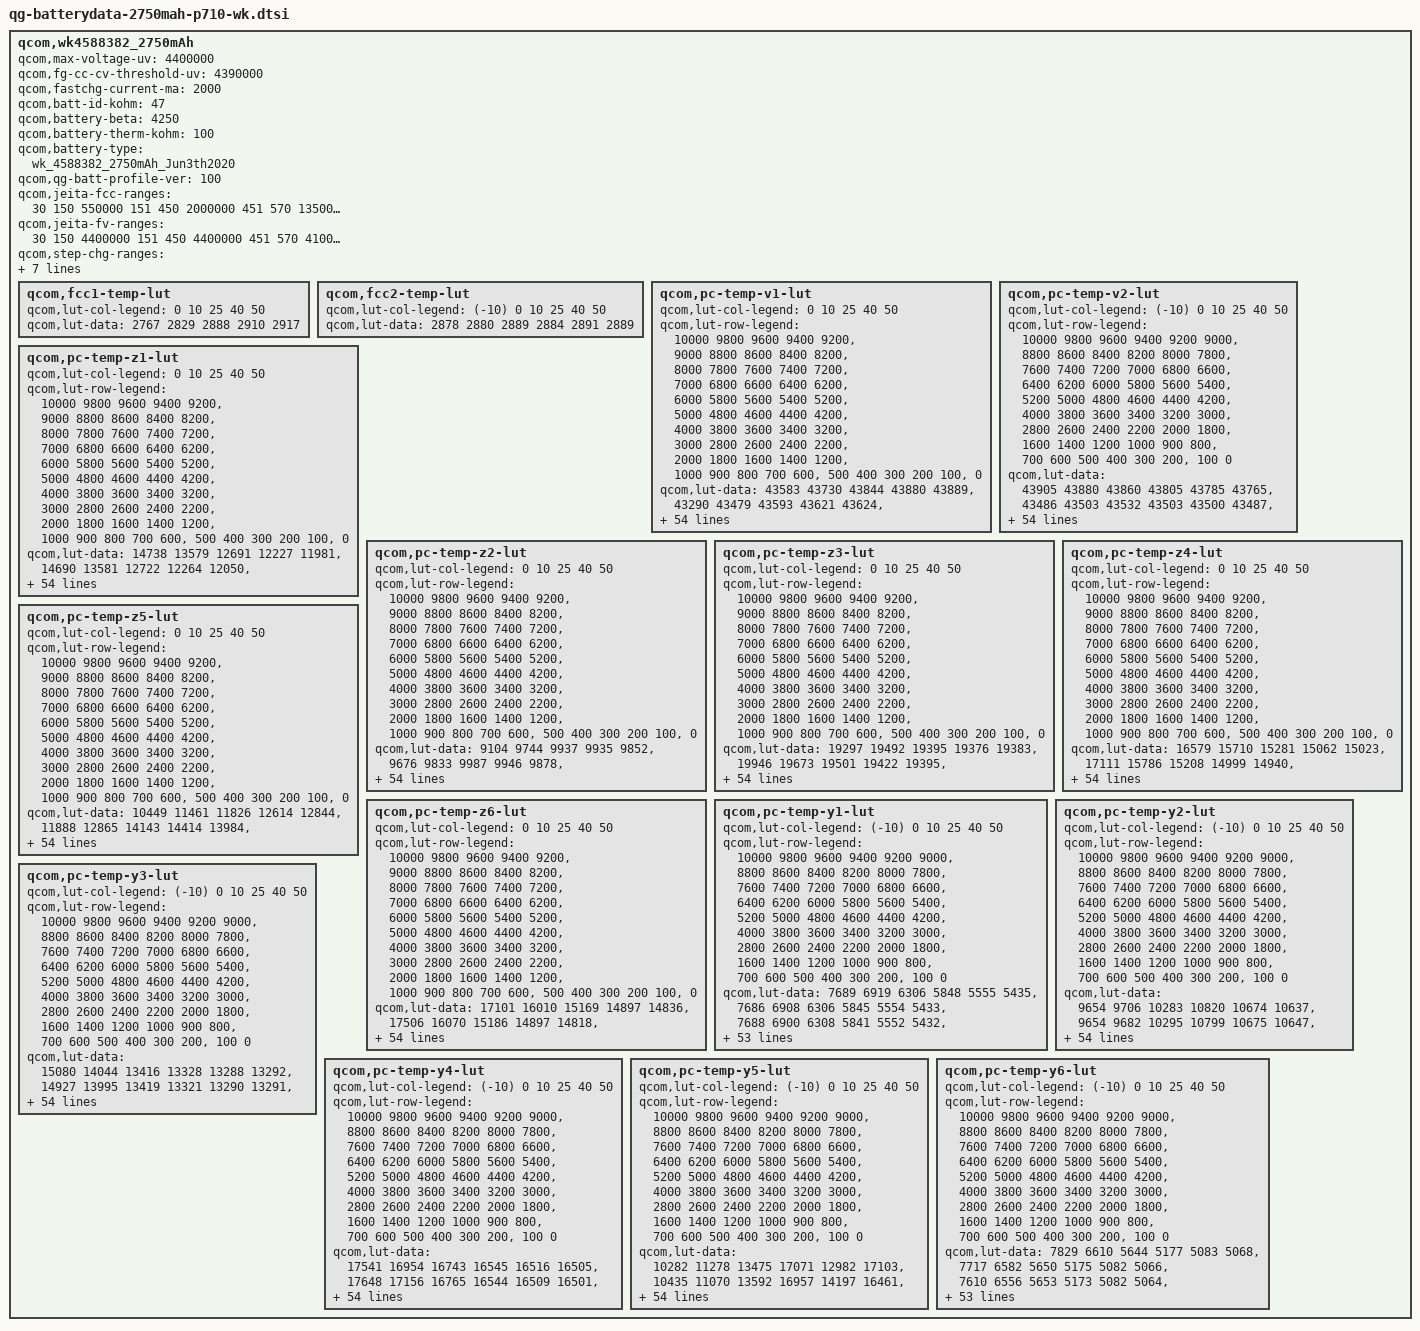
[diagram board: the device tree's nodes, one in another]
/*
 * Copyright (c) 2018-2019, The Linux Foundation. All rights reserved.
 *
 * This program is free software; you can redistribute it and/or modify
 * it under the terms of the GNU General Public License version 2 and
 * only version 2 as published by the Free Software Foundation.
 *
 * This program is distributed in the hope that it will be useful,
 * but WITHOUT ANY WARRANTY; without even the implied warranty of
 * MERCHANTABILITY or FITNESS FOR A PARTICULAR PURPOSE.  See the
 * GNU General Public License for more details.
 */

qcom,wk4588382_2750mAh {
	/* wk4588382_2750mAh_averaged_MasterSlave_Jun3th2020 */
	qcom,max-voltage-uv = <4400000>;
	qcom,fg-cc-cv-threshold-uv = <4390000>;
	qcom,fastchg-current-ma = <2000>;
	qcom,batt-id-kohm = <47>;
	qcom,battery-beta = <4250>;
	qcom,battery-therm-kohm = <100>;
	qcom,battery-type = "wk_4588382_2750mAh_Jun3th2020";
	qcom,qg-batt-profile-ver = <100>;

	qcom,jeita-fcc-ranges = <30  150   550000
				151  450  2000000
				451  570  1350000>;
	qcom,jeita-fv-ranges = <30   150   4400000
				151  450  4400000
				451  570  4100000>;
	qcom,step-chg-ranges = <3600000  3800000  5400000
				3800001  4300000  3600000
				4300001  4350000  2500000>;
	qcom,ocv-based-step-chg;

	/* COOL = 15 DegC, WARM = 45 DegC */
	qcom,jeita-soft-thresholds = <0x45E7 0x20C1>;
	
	/* COLD = 3 DegC, HOT = 57 DegC */
	qcom,jeita-hard-thresholds = <0x54E5 0x1694>;
	
	/* COOL hys = 17 DegC, WARM hys = 42 DegC */
	qcom,jeita-soft-hys-thresholds = <0x4341 0x23D3>;
	
	qcom,jeita-soft-fcc-ua = <550000 1350000>;
	qcom,jeita-soft-fv-uv = <4400000 4100000>;

	qcom,fcc1-temp-lut {
		qcom,lut-col-legend = <0 10 25 40 50>;
		qcom,lut-data = <2767 2829 2888 2910 2917>;
	};

	qcom,fcc2-temp-lut {
		qcom,lut-col-legend = <(-10) 0 10 25 40 50>;
		qcom,lut-data = <2878 2880 2889 2884 2891 2889>;
	};

	qcom,pc-temp-v1-lut {
		qcom,lut-col-legend = <0 10 25 40 50>;
		qcom,lut-row-legend = <10000 9800 9600 9400 9200>,
			<9000 8800 8600 8400 8200>,
			<8000 7800 7600 7400 7200>,
			<7000 6800 6600 6400 6200>,
			<6000 5800 5600 5400 5200>,
			<5000 4800 4600 4400 4200>,
			<4000 3800 3600 3400 3200>,
			<3000 2800 2600 2400 2200>,
			<2000 1800 1600 1400 1200>,
			<1000 900 800 700 600>,
			<500 400 300 200 100>,
			<0>;
		qcom,lut-data = <43583 43730 43844 43880 43889>,
			<43290 43479 43593 43621 43624>,
			<43034 43220 43347 43384 43385>,
			<42791 42977 43105 43149 43154>,
			<42556 42738 42863 42910 42921>,
			<42330 42500 42624 42670 42689>,
			<42113 42269 42385 42435 42455>,
			<41904 42047 42150 42203 42219>,
			<41698 41833 41921 41971 41986>,
			<41493 41622 41697 41738 41754>,
			<41293 41411 41475 41511 41526>,
			<41111 41210 41254 41289 41305>,
			<40939 41034 41048 41072 41089>,
			<40728 40865 40872 40865 40877>,
			<40425 40642 40696 40663 40670>,
			<40132 40327 40464 40464 40470>,
			<39949 40065 40191 40264 40277>,
			<39811 39919 39994 40078 40095>,
			<39681 39804 39869 39913 39925>,
			<39560 39683 39747 39756 39761>,
			<39442 39563 39596 39595 39597>,
			<39324 39421 39425 39432 39434>,
			<39205 39222 39208 39242 39249>,
			<39088 39007 38929 38993 39010>,
			<38973 38820 38740 38784 38798>,
			<38857 38650 38645 38663 38667>,
			<38735 38539 38570 38569 38564>,
			<38613 38474 38491 38473 38465>,
			<38514 38421 38416 38380 38371>,
			<38431 38373 38344 38296 38287>,
			<38366 38330 38274 38221 38212>,
			<38317 38290 38212 38155 38143>,
			<38279 38253 38160 38100 38081>,
			<38245 38218 38113 38050 38023>,
			<38216 38185 38074 38001 37968>,
			<38187 38151 38041 37952 37914>,
			<38163 38116 38002 37903 37858>,
			<38138 38079 37961 37857 37800>,
			<38099 38030 37908 37803 37734>,
			<38027 37946 37830 37725 37652>,
			<37935 37838 37724 37622 37552>,
			<37818 37720 37609 37507 37438>,
			<37679 37582 37476 37372 37303>,
			<37520 37420 37320 37220 37151>,
			<37367 37273 37168 37073 37006>,
			<37253 37190 37073 36983 36925>,
			<37215 37159 37049 36958 36900>,
			<37187 37131 37032 36941 36882>,
			<37164 37108 37014 36923 36865>,
			<37127 37073 36976 36878 36813>,
			<36954 36887 36774 36652 36566>,
			<36534 36469 36350 36218 36123>,
			<35968 35898 35779 35645 35550>,
			<35199 35119 34998 34863 34765>,
			<33992 33914 33795 33656 33553>,
			<30000 30000 30000 30000 30000>;
	};

	qcom,pc-temp-v2-lut {
		qcom,lut-col-legend = <(-10) 0 10 25 40 50>;
		qcom,lut-row-legend = <10000 9800 9600 9400 9200 9000>,
			<8800 8600 8400 8200 8000 7800>,
			<7600 7400 7200 7000 6800 6600>,
			<6400 6200 6000 5800 5600 5400>,
			<5200 5000 4800 4600 4400 4200>,
			<4000 3800 3600 3400 3200 3000>,
			<2800 2600 2400 2200 2000 1800>,
			<1600 1400 1200 1000 900 800>,
			<700 600 500 400 300 200>,
			<100 0>;
		qcom,lut-data = <43905 43880 43860 43805 43785 43765>,
			<43486 43503 43532 43503 43500 43487>,
			<43110 43157 43228 43220 43231 43222>,
			<42782 42845 42950 42958 42977 42970>,
			<42493 42561 42696 42715 42739 42731>,
			<42226 42302 42448 42476 42503 42494>,
			<41976 42072 42201 42240 42267 42259>,
			<41744 41847 41962 42008 42033 42026>,
			<41515 41590 41731 41781 41802 41796>,
			<41304 41332 41507 41556 41575 41568>,
			<41174 41157 41293 41332 41350 41344>,
			<41105 41051 41090 41109 41130 41127>,
			<41000 40912 40893 40901 40915 40913>,
			<40566 40634 40712 40727 40710 40705>,
			<40003 40291 40521 40553 40509 40502>,
			<39715 40006 40266 40322 40311 40306>,
			<39527 39743 39961 40047 40115 40117>,
			<39348 39517 39746 39847 39935 39937>,
			<39172 39329 39613 39723 39772 39769>,
			<39002 39152 39472 39594 39606 39600>,
			<38833 38974 39258 39406 39430 39429>,
			<38673 38801 39016 39187 39245 39251>,
			<38544 38633 38824 38977 39038 39047>,
			<38438 38466 38659 38769 38808 38813>,
			<38346 38337 38517 38600 38627 38630>,
			<38267 38250 38395 38476 38501 38503>,
			<38197 38180 38286 38371 38394 38395>,
			<38134 38118 38181 38272 38294 38294>,
			<38076 38064 38085 38183 38204 38203>,
			<38020 38016 38013 38103 38121 38118>,
			<37965 37972 37959 38031 38045 38041>,
			<37912 37931 37912 37963 37975 37970>,
			<37862 37892 37871 37901 37916 37911>,
			<37812 37853 37833 37842 37858 37852>,
			<37761 37812 37797 37790 37792 37779>,
			<37709 37769 37760 37742 37719 37694>,
			<37653 37722 37717 37689 37639 37602>,
			<37595 37673 37666 37626 37550 37499>,
			<37531 37616 37606 37557 37463 37400>,
			<37458 37544 37533 37482 37385 37319>,
			<37378 37459 37446 37399 37307 37241>,
			<37298 37359 37342 37304 37214 37150>,
			<37219 37239 37216 37188 37098 37035>,
			<37134 37105 37082 37049 36965 36903>,
			<37048 36974 36948 36912 36838 36781>,
			<36959 36894 36871 36871 36812 36756>,
			<36915 36863 36840 36858 36800 36746>,
			<36865 36832 36809 36838 36784 36731>,
			<36798 36787 36760 36810 36758 36703>,
			<36673 36701 36664 36733 36660 36590>,
			<36428 36480 36435 36456 36328 36239>,
			<36001 36041 35959 35961 35817 35726>,
			<35376 35408 35310 35322 35155 35058>,
			<34467 34497 34391 34466 34262 34161>,
			<32983 33139 33114 33148 32998 32889>,
			<28849 28709 27892 28006 28079 28058>;
	};

	qcom,pc-temp-z1-lut {
		qcom,lut-col-legend = <0 10 25 40 50>;
		qcom,lut-row-legend = <10000 9800 9600 9400 9200>,
			<9000 8800 8600 8400 8200>,
			<8000 7800 7600 7400 7200>,
			<7000 6800 6600 6400 6200>,
			<6000 5800 5600 5400 5200>,
			<5000 4800 4600 4400 4200>,
			<4000 3800 3600 3400 3200>,
			<3000 2800 2600 2400 2200>,
			<2000 1800 1600 1400 1200>,
			<1000 900 800 700 600>,
			<500 400 300 200 100>,
			<0>;
		qcom,lut-data = <14738 13579 12691 12227 11981>,
			<14690 13581 12722 12264 12050>,
			<14733 13571 12731 12247 12046>,
			<14751 13561 12729 12235 12037>,
			<14702 13551 12720 12222 12028>,
			<14639 13539 12708 12209 12022>,
			<14623 13530 12687 12199 12018>,
			<14616 13529 12666 12191 12016>,
			<14608 13531 12658 12187 12013>,
			<14590 13525 12651 12183 12009>,
			<14562 13514 12652 12181 12006>,
			<14525 13500 12658 12180 12004>,
			<14475 13474 12661 12178 12003>,
			<14449 13437 12651 12176 12001>,
			<14442 13412 12636 12172 11999>,
			<14435 13389 12626 12170 11998>,
			<14417 13379 12619 12168 12000>,
			<14391 13382 12618 12168 12001>,
			<14386 13390 12624 12169 12001>,
			<14403 13405 12628 12170 12001>,
			<14419 13432 12632 12169 12000>,
			<14414 13445 12639 12168 11999>,
			<14396 13443 12640 12167 11999>,
			<14392 13441 12637 12169 12001>,
			<14421 13446 12637 12172 12003>,
			<14455 13459 12642 12175 12006>,
			<14474 13464 12649 12180 12010>,
			<14487 13466 12654 12183 12014>,
			<14489 13471 12659 12187 12017>,
			<14465 13482 12665 12191 12021>,
			<14444 13496 12676 12196 12025>,
			<14459 13498 12684 12202 12028>,
			<14488 13489 12687 12207 12032>,
			<14496 13483 12690 12212 12035>,
			<14491 13489 12690 12217 12039>,
			<14493 13503 12690 12222 12044>,
			<14513 13521 12694 12227 12049>,
			<14547 13547 12704 12231 12053>,
			<14580 13562 12715 12236 12056>,
			<14621 13565 12721 12242 12061>,
			<14643 13567 12726 12247 12066>,
			<14624 13580 12734 12254 12070>,
			<14603 13603 12744 12261 12073>,
			<14641 13622 12751 12265 12076>,
			<14665 13627 12757 12268 12078>,
			<14653 13621 12751 12270 12079>,
			<14680 13620 12745 12269 12080>,
			<14639 13618 12752 12273 12082>,
			<14759 13629 12759 12278 12085>,
			<14655 13636 12758 12283 12094>,
			<14676 13662 12782 12293 12102>,
			<14718 13664 12779 12306 12113>,
			<14746 13706 12828 12319 12126>,
			<14813 13781 12830 12341 12146>,
			<14813 13781 12830 12341 12146>,
			<14813 13781 12830 12341 12146>;
	};

	qcom,pc-temp-z2-lut {
		qcom,lut-col-legend = <0 10 25 40 50>;
		qcom,lut-row-legend = <10000 9800 9600 9400 9200>,
			<9000 8800 8600 8400 8200>,
			<8000 7800 7600 7400 7200>,
			<7000 6800 6600 6400 6200>,
			<6000 5800 5600 5400 5200>,
			<5000 4800 4600 4400 4200>,
			<4000 3800 3600 3400 3200>,
			<3000 2800 2600 2400 2200>,
			<2000 1800 1600 1400 1200>,
			<1000 900 800 700 600>,
			<500 400 300 200 100>,
			<0>;
		qcom,lut-data = <9104 9744 9937 9935 9852>,
			<9676 9833 9987 9946 9878>,
			<9710 9839 9998 9979 9871>,
			<9722 9820 9990 10025 10016>,
			<9729 9798 9959 10005 9987>,
			<9733 9777 9929 9977 9947>,
			<9741 9759 9898 9957 9935>,
			<9752 9745 9879 9940 9932>,
			<9755 9734 9884 9938 9934>,
			<9750 9728 9900 9942 9943>,
			<9742 9724 9908 9943 9947>,
			<9737 9722 9911 9939 9903>,
			<9731 9740 9915 9934 9844>,
			<9719 9776 9930 9919 9841>,
			<9672 9785 9946 9893 9849>,
			<9631 9782 9945 9890 9854>,
			<9633 9780 9940 9922 9860>,
			<9646 9794 9939 9941 9865>,
			<9659 9821 9948 9924 9874>,
			<9673 9843 9960 9904 9888>,
			<9683 9866 9973 9904 9904>,
			<9685 9875 9984 9910 9925>,
			<9686 9873 9984 9918 9941>,
			<9687 9868 9977 9941 9952>,
			<9688 9852 9971 9958 9966>,
			<9690 9817 9966 9950 10037>,
			<9696 9807 9964 9937 10138>,
			<9706 9830 9973 9951 10129>,
			<9716 9855 9994 9986 10010>,
			<9726 9862 9997 9998 9907>,
			<9735 9867 9979 9974 9833>,
			<9743 9872 9967 9943 9789>,
			<9750 9878 9969 9919 9794>,
			<9761 9885 9974 9900 9812>,
			<9782 9893 9980 9908 9833>,
			<9795 9901 9993 9965 9861>,
			<9722 9909 10006 10005 9893>,
			<9589 9917 10020 10020 9931>,
			<9564 9927 10036 10028 9964>,
			<9620 9942 10056 10036 9982>,
			<9702 9955 10075 10055 9994>,
			<9869 9957 10085 10073 9999>,
			<10039 9958 10090 10099 9999>,
			<9973 9969 10094 10099 9997>,
			<9918 9993 10106 10082 9988>,
			<9913 12962 10144 10046 9973>,
			<9777 13619 10131 10041 9983>,
			<9969 10888 10120 10045 9998>,
			<9985 16588 10135 10053 10030>,
			<9920 12525 10180 10122 10092>,
			<9695 14166 10223 10077 9975>,
			<9622 13638 10223 9990 9860>,
			<9549 10993 10191 9962 9824>,
			<9425 9996 10134 9918 9797>,
			<9425 9996 10134 9918 9797>,
			<9425 9996 10134 9918 9797>;
	};

	qcom,pc-temp-z3-lut {
		qcom,lut-col-legend = <0 10 25 40 50>;
		qcom,lut-row-legend = <10000 9800 9600 9400 9200>,
			<9000 8800 8600 8400 8200>,
			<8000 7800 7600 7400 7200>,
			<7000 6800 6600 6400 6200>,
			<6000 5800 5600 5400 5200>,
			<5000 4800 4600 4400 4200>,
			<4000 3800 3600 3400 3200>,
			<3000 2800 2600 2400 2200>,
			<2000 1800 1600 1400 1200>,
			<1000 900 800 700 600>,
			<500 400 300 200 100>,
			<0>;
		qcom,lut-data = <19297 19492 19395 19376 19383>,
			<19946 19673 19501 19422 19395>,
			<20080 19782 19535 19431 19411>,
			<20109 19817 19588 19487 19464>,
			<20104 19832 19596 19503 19471>,
			<20095 19836 19599 19509 19473>,
			<20072 19835 19599 19502 19471>,
			<20030 19826 19599 19487 19466>,
			<20007 19809 19590 19480 19462>,
			<19997 19798 19569 19476 19459>,
			<19988 19792 19560 19471 19455>,
			<19959 19785 19558 19461 19443>,
			<19909 19753 19554 19450 19430>,
			<19898 19700 19534 19443 19424>,
			<20008 19690 19513 19436 19421>,
			<20117 19722 19515 19435 19417>,
			<20095 19744 19526 19435 19414>,
			<20014 19720 19527 19435 19409>,
			<19951 19678 19507 19425 19401>,
			<19905 19653 19490 19413 19392>,
			<19876 19635 19495 19412 19390>,
			<19871 19629 19504 19413 19390>,
			<19868 19670 19510 19414 19390>,
			<19870 19717 19515 19413 19388>,
			<19888 19722 19516 19412 19387>,
			<19912 19723 19504 19410 19406>,
			<19936 19722 19491 19407 19440>,
			<19959 19717 19496 19420 19452>,
			<19964 19709 19511 19464 19459>,
			<19955 19702 19525 19481 19461>,
			<19942 19695 19540 19478 19451>,
			<19926 19687 19548 19471 19437>,
			<19904 19678 19543 19461 19429>,
			<19879 19671 19535 19448 19421>,
			<19849 19667 19525 19439 19412>,
			<19804 19663 19514 19432 19400>,
			<19616 19659 19507 19426 19394>,
			<19338 19652 19503 19421 19395>,
			<19269 19647 19499 19417 19395>,
			<19267 19645 19494 19413 19394>,
			<19266 19642 19488 19409 19391>,
			<19264 19639 19482 19408 19391>,
			<19262 19632 19475 19411 19395>,
			<19262 19626 19474 19412 19399>,
			<19262 19567 19471 19410 19401>,
			<19262 19298 19448 19392 19381>,
			<19263 19261 19434 19385 19372>,
			<19261 19261 19417 19379 19366>,
			<19261 19257 19408 19377 19353>,
			<19262 19260 19399 19368 19343>,
			<19264 19257 19391 19385 19383>,
			<19265 19258 19385 19398 19395>,
			<19267 19259 19382 19403 19398>,
			<19270 19263 19397 19405 19403>,
			<19270 19263 19397 19405 19403>,
			<19270 19263 19397 19405 19403>;
	};

	qcom,pc-temp-z4-lut {
		qcom,lut-col-legend = <0 10 25 40 50>;
		qcom,lut-row-legend = <10000 9800 9600 9400 9200>,
			<9000 8800 8600 8400 8200>,
			<8000 7800 7600 7400 7200>,
			<7000 6800 6600 6400 6200>,
			<6000 5800 5600 5400 5200>,
			<5000 4800 4600 4400 4200>,
			<4000 3800 3600 3400 3200>,
			<3000 2800 2600 2400 2200>,
			<2000 1800 1600 1400 1200>,
			<1000 900 800 700 600>,
			<500 400 300 200 100>,
			<0>;
		qcom,lut-data = <16579 15710 15281 15062 15023>,
			<17111 15786 15208 14999 14940>,
			<16830 15977 15100 14908 14869>,
			<16535 15690 15257 15046 14978>,
			<16266 15432 15132 14993 14946>,
			<16022 15283 15024 14925 14894>,
			<15851 15169 14955 14885 14861>,
			<15714 15085 14902 14854 14834>,
			<15599 15021 14866 14834 14816>,
			<15495 14968 14840 14820 14804>,
			<15411 14921 14823 14810 14796>,
			<15354 14886 14813 14801 14792>,
			<15312 14868 14802 14793 14788>,
			<15250 14856 14782 14782 14781>,
			<15122 14852 14766 14770 14769>,
			<15016 14851 14769 14758 14758>,
			<14999 14850 14781 14747 14749>,
			<14992 14834 14782 14739 14741>,
			<14989 14811 14751 14731 14733>,
			<14988 14802 14726 14726 14727>,
			<14986 14797 14728 14728 14728>,
			<14976 14796 14734 14737 14738>,
			<14955 14817 14779 14763 14760>,
			<14932 14857 14933 14885 14868>,
			<14899 14910 15004 14970 14954>,
			<14873 14979 14990 14961 14925>,
			<14867 14999 14963 14937 14862>,
			<14864 14971 14928 14896 14822>,
			<14864 14932 14879 14824 14790>,
			<14869 14903 14839 14782 14769>,
			<14873 14875 14802 14766 14759>,
			<14868 14851 14779 14755 14752>,
			<14858 14829 14769 14746 14742>,
			<14856 14809 14762 14740 14734>,
			<14863 14792 14756 14739 14733>,
			<14876 14777 14750 14742 14736>,
			<15043 14767 14748 14743 14740>,
			<15333 14759 14746 14743 14743>,
			<15401 14756 14745 14743 14746>,
			<15384 14760 14751 14749 14751>,
			<15368 14765 14761 14759 14757>,
			<15361 14763 14760 14759 14757>,
			<15355 14758 14750 14746 14746>,
			<15336 14756 14748 14746 14746>,
			<15247 14788 14745 14749 14750>,
			<15170 14994 14708 14715 14714>,
			<15163 15026 14707 14708 14708>,
			<15156 15015 14704 14686 14686>,
			<15147 15008 14699 14661 14666>,
			<15133 14997 14702 14664 14667>,
			<15135 15009 14737 14689 14680>,
			<15164 15029 14757 14697 14692>,
			<15183 15038 14767 14697 14695>,
			<15210 15046 14757 14701 14693>,
			<15210 15046 14757 14701 14693>,
			<15210 15046 14757 14701 14693>;
	};

	qcom,pc-temp-z5-lut {
		qcom,lut-col-legend = <0 10 25 40 50>;
		qcom,lut-row-legend = <10000 9800 9600 9400 9200>,
			<9000 8800 8600 8400 8200>,
			<8000 7800 7600 7400 7200>,
			<7000 6800 6600 6400 6200>,
			<6000 5800 5600 5400 5200>,
			<5000 4800 4600 4400 4200>,
			<4000 3800 3600 3400 3200>,
			<3000 2800 2600 2400 2200>,
			<2000 1800 1600 1400 1200>,
			<1000 900 800 700 600>,
			<500 400 300 200 100>,
			<0>;
		qcom,lut-data = <10449 11461 11826 12614 12844>,
			<11888 12865 14143 14414 13984>,
			<12337 13125 15584 15732 15728>,
			<12574 13631 14605 15094 15762>,
			<12745 14173 15077 15717 15956>,
			<12846 14643 15646 16367 16209>,
			<12883 15028 16348 16491 16562>,
			<12897 15250 16986 16555 17035>,
			<12928 15413 17300 16742 17457>,
			<13073 15702 17521 17160 17896>,
			<13198 16483 17924 17339 18090>,
			<13065 17111 18684 17185 17608>,
			<12687 16685 19071 17036 16985>,
			<12711 15712 18591 17115 17064>,
			<15464 15927 17990 17382 17565>,
			<18227 19107 18494 17867 18117>,
			<17795 21316 20089 19123 18830>,
			<16105 20064 20599 19839 19241>,
			<15027 18049 20169 19789 19212>,
			<14446 17418 19836 19729 19160>,
			<14142 17163 22517 20101 19408>,
			<14259 17332 26945 21176 20221>,
			<14669 26820 27547 21368 20367>,
			<15283 38051 26852 19658 18139>,
			<16709 37999 25654 17624 16104>,
			<18892 34081 21479 15851 15889>,
			<23153 30678 17673 14424 16044>,
			<28791 28105 17566 14930 16757>,
			<30316 26062 17846 17649 18500>,
			<30083 24664 18676 20096 19549>,
			<29645 23609 22143 22112 19799>,
			<28230 23075 25593 23512 20038>,
			<25475 22748 28036 24146 20982>,
			<22844 22615 29739 24581 22335>,
			<20283 23186 29739 24921 22594>,
			<17658 24194 29271 25938 22522>,
			<14384 24534 29052 26390 22489>,
			<11246 24750 28791 25611 22857>,
			<10573 24885 28376 24308 23270>,
			<10584 25555 27146 22534 22284>,
			<10599 26320 25044 20360 19884>,
			<10609 25874 23439 19959 19347>,
			<10621 24584 22125 20332 19990>,
			<10641 24235 21892 20141 20268>,
			<10753 22052 21823 19408 20182>,
			<10834 12369 21603 18835 18439>,
			<10825 10897 19603 17913 17104>,
			<10818 10886 17223 18124 17578>,
			<10788 10863 16435 20522 17882>,
			<10804 10888 15930 18845 16363>,
			<10869 10917 14623 17397 18666>,
			<10842 10868 13777 17122 18218>,
			<10794 10839 13356 16972 17143>,
			<10727 10796 13755 16192 16520>,
			<10727 10796 13755 16192 16520>,
			<10727 10796 13755 16192 16520>;
	};

	qcom,pc-temp-z6-lut {
		qcom,lut-col-legend = <0 10 25 40 50>;
		qcom,lut-row-legend = <10000 9800 9600 9400 9200>,
			<9000 8800 8600 8400 8200>,
			<8000 7800 7600 7400 7200>,
			<7000 6800 6600 6400 6200>,
			<6000 5800 5600 5400 5200>,
			<5000 4800 4600 4400 4200>,
			<4000 3800 3600 3400 3200>,
			<3000 2800 2600 2400 2200>,
			<2000 1800 1600 1400 1200>,
			<1000 900 800 700 600>,
			<500 400 300 200 100>,
			<0>;
		qcom,lut-data = <17101 16010 15169 14897 14836>,
			<17506 16070 15186 14897 14818>,
			<17349 16158 15143 14861 14795>,
			<17169 15998 15229 14945 14870>,
			<16978 15845 15171 14928 14858>,
			<16788 15747 15118 14902 14838>,
			<16640 15664 15081 14879 14822>,
			<16515 15595 15050 14857 14806>,
			<16412 15536 15023 14843 14796>,
			<16332 15489 15001 14834 14789>,
			<16259 15453 14990 14825 14782>,
			<16178 15420 14984 14816 14773>,
			<16096 15377 14977 14807 14764>,
			<16039 15335 14953 14797 14756>,
			<16006 15326 14929 14787 14749>,
			<15977 15330 14930 14780 14742>,
			<15938 15332 14937 14776 14736>,
			<15895 15315 14937 14771 14730>,
			<15867 15285 14916 14762 14721>,
			<15850 15274 14899 14753 14714>,
			<15839 15269 14902 14754 14714>,
			<15835 15268 14910 14758 14718>,
			<15832 15298 14936 14770 14727>,
			<15831 15343 15005 14822 14773>,
			<15834 15376 15036 14859 14810>,
			<15838 15404 15025 14854 14808>,
			<15849 15412 15010 14844 14801>,
			<15865 15401 14998 14836 14793>,
			<15871 15386 14988 14829 14785>,
			<15871 15373 14980 14821 14776>,
			<15871 15359 14975 14814 14766>,
			<15867 15347 14969 14806 14757>,
			<15856 15336 14964 14797 14748>,
			<15846 15328 14959 14788 14741>,
			<15837 15323 14953 14783 14736>,
			<15828 15320 14946 14781 14731>,
			<15820 15320 14944 14779 14729>,
			<15813 15320 14944 14776 14730>,
			<15812 15321 14944 14775 14732>,
			<15817 15328 14947 14776 14733>,
			<15824 15338 14951 14780 14735>,
			<15834 15342 14951 14780 14735>,
			<15845 15345 14946 14777 14734>,
			<15851 15352 14947 14778 14736>,
			<15836 15348 14949 14780 14739>,
			<15816 15319 14926 14756 14713>,
			<15818 15316 14920 14750 14706>,
			<15816 15312 14910 14737 14694>,
			<15816 15311 14905 14726 14678>,
			<15822 15315 14906 14725 14675>,
			<15838 15331 14922 14746 14703>,
			<15864 15351 14933 14760 14718>,
			<15894 15371 14942 14767 14725>,
			<15937 15398 14956 14775 14732>,
			<15937 15398 14956 14775 14732>,
			<15937 15398 14956 14775 14732>;
	};

	qcom,pc-temp-y1-lut {
		qcom,lut-col-legend = <(-10) 0 10 25 40 50>;
		qcom,lut-row-legend = <10000 9800 9600 9400 9200 9000>,
			<8800 8600 8400 8200 8000 7800>,
			<7600 7400 7200 7000 6800 6600>,
			<6400 6200 6000 5800 5600 5400>,
			<5200 5000 4800 4600 4400 4200>,
			<4000 3800 3600 3400 3200 3000>,
			<2800 2600 2400 2200 2000 1800>,
			<1600 1400 1200 1000 900 800>,
			<700 600 500 400 300 200>,
			<100 0>;
		qcom,lut-data = <7689 6919 6306 5848 5555 5435>,
			<7686 6908 6306 5845 5554 5433>,
			<7688 6900 6308 5841 5552 5432>,
			<7691 6896 6310 5838 5550 5430>,
			<7694 6893 6311 5835 5548 5428>,
			<7695 6890 6310 5833 5546 5427>,
			<7695 6884 6307 5826 5543 5426>,
			<7697 6880 6306 5820 5541 5426>,
			<7713 6877 6304 5819 5537 5424>,
			<7736 6869 6300 5821 5532 5421>,
			<7735 6865 6301 5820 5531 5418>,
			<7694 6854 6306 5815 5530 5415>,
			<7670 6846 6310 5810 5530 5413>,
			<7685 6851 6311 5804 5527 5413>,
			<7704 6861 6312 5800 5523 5413>,
			<7703 6865 6317 5804 5522 5412>,
			<7692 6870 6327 5817 5521 5411>,
			<7693 6874 6330 5821 5521 5410>,
			<7721 6886 6333 5817 5522 5410>,
			<7749 6896 6334 5814 5522 5410>,
			<7746 6898 6322 5815 5521 5409>,
			<7731 6898 6307 5817 5520 5409>,
			<7733 6896 6307 5817 5520 5409>,
			<7740 6891 6314 5816 5519 5410>,
			<7742 6885 6318 5816 5519 5410>,
			<7741 6876 6323 5820 5521 5411>,
			<7738 6870 6326 5823 5523 5412>,
			<7720 6876 6321 5823 5525 5413>,
			<7683 6890 6312 5823 5529 5416>,
			<7673 6897 6313 5825 5532 5418>,
			<7687 6906 6324 5834 5535 5421>,
			<7699 6913 6333 5841 5538 5423>,
			<7688 6905 6329 5843 5541 5425>,
			<7673 6890 6322 5844 5545 5427>,
			<7675 6883 6318 5846 5548 5430>,
			<7697 6872 6311 5852 5551 5433>,
			<7709 6869 6310 5855 5553 5435>,
			<7707 6865 6325 5853 5554 5437>,
			<7704 6860 6338 5850 5555 5438>,
			<7714 6863 6339 5849 5557 5441>,
			<7732 6869 6339 5849 5560 5443>,
			<7698 6880 6327 5849 5562 5446>,
			<7678 6898 6320 5861 5567 5448>,
			<7737 6921 6352 5865 5574 5452>,
			<7783 6927 6332 5862 5578 5459>,
			<7751 6918 6334 5872 5588 5464>,
			<7740 6927 6350 5882 5589 5461>,
			<7775 6922 6362 5885 5585 5463>,
			<7761 6925 6347 5878 5587 5462>,
			<7777 6947 6351 5880 5583 5462>,
			<7830 6936 6352 5894 5589 5466>,
			<7774 6943 6374 5899 5599 5474>,
			<7790 6964 6390 5933 5614 5483>,
			<7865 7009 6426 5942 5629 5498>,
			<7865 7009 6426 5942 5629 5498>,
			<7865 7009 6426 5942 5629 5498>;
	};

	qcom,pc-temp-y2-lut {
		qcom,lut-col-legend = <(-10) 0 10 25 40 50>;
		qcom,lut-row-legend = <10000 9800 9600 9400 9200 9000>,
			<8800 8600 8400 8200 8000 7800>,
			<7600 7400 7200 7000 6800 6600>,
			<6400 6200 6000 5800 5600 5400>,
			<5200 5000 4800 4600 4400 4200>,
			<4000 3800 3600 3400 3200 3000>,
			<2800 2600 2400 2200 2000 1800>,
			<1600 1400 1200 1000 900 800>,
			<700 600 500 400 300 200>,
			<100 0>;
		qcom,lut-data = <9654 9706 10283 10820 10674 10637>,
			<9654 9682 10295 10799 10675 10647>,
			<9655 9671 10309 10760 10668 10646>,
			<9655 9673 10321 10715 10655 10639>,
			<9656 9683 10328 10678 10641 10628>,
			<9656 9702 10330 10658 10627 10616>,
			<9657 9778 10324 10643 10608 10595>,
			<9657 9883 10317 10629 10591 10578>,
			<9657 10004 10312 10616 10576 10573>,
			<9657 10127 10307 10601 10559 10564>,
			<9657 10127 10305 10588 10551 10550>,
			<9657 9972 10304 10573 10547 10518>,
			<9657 9876 10311 10565 10543 10501>,
			<9657 9997 10421 10565 10530 10509>,
			<9657 10155 10544 10568 10518 10518>,
			<9656 10073 10538 10581 10534 10514>,
			<9656 9780 10499 10616 10586 10505>,
			<9656 9672 10490 10656 10623 10505>,
			<9656 9670 10524 10715 10642 10534>,
			<9656 9669 10552 10750 10666 10578>,
			<9655 9667 10555 10747 10729 10673>,
			<9655 9666 10558 10740 10798 10782>,
			<9655 9666 10567 10737 10789 10775>,
			<9655 9666 10590 10737 10721 10699>,
			<9655 9666 10611 10741 10693 10665>,
			<9655 9665 10631 10758 10715 10670>,
			<9655 9664 10643 10783 10736 10680>,
			<9655 9663 10559 10810 10742 10706>,
			<9655 9662 10351 10841 10751 10744>,
			<9655 9661 10200 10854 10762 10758>,
			<9654 9659 10072 10852 10775 10760>,
			<9654 9658 10023 10848 10786 10766>,
			<9654 9658 10248 10853 10802 10799>,
			<9654 9657 10522 10861 10819 10835>,
			<9654 9656 10503 10851 10822 10827>,
			<9654 9656 10339 10818 10825 10792>,
			<9654 9655 10189 10805 10820 10771>,
			<9654 9655 9991 10813 10787 10767>,
			<9654 9654 9834 10820 10761 10761>,
			<9654 9654 9767 10806 10776 10734>,
			<9653 9654 9723 10777 10790 10710>,
			<9653 9653 9691 10738 10769 10708>,
			<9653 9653 9676 10710 10763 10689>,
			<9653 9653 9677 10733 10814 10713>,
			<9653 9653 9670 10652 10752 10687>,
			<9653 9652 9663 10607 10712 10599>,
			<9653 9652 9662 10600 10659 10546>,
			<9652 9652 9660 10586 10672 10540>,
			<9652 9652 9658 10576 10715 10580>,
			<9652 9652 9657 10566 10676 10541>,
			<9652 9651 9656 10526 10639 10526>,
			<9652 9651 9655 10452 10568 10468>,
			<9652 9651 9653 10399 10527 10395>,
			<9651 9651 9652 10364 10446 10312>,
			<9651 9651 9652 10364 10446 10312>,
			<9651 9651 9652 10364 10446 10312>;
	};

	qcom,pc-temp-y3-lut {
		qcom,lut-col-legend = <(-10) 0 10 25 40 50>;
		qcom,lut-row-legend = <10000 9800 9600 9400 9200 9000>,
			<8800 8600 8400 8200 8000 7800>,
			<7600 7400 7200 7000 6800 6600>,
			<6400 6200 6000 5800 5600 5400>,
			<5200 5000 4800 4600 4400 4200>,
			<4000 3800 3600 3400 3200 3000>,
			<2800 2600 2400 2200 2000 1800>,
			<1600 1400 1200 1000 900 800>,
			<700 600 500 400 300 200>,
			<100 0>;
		qcom,lut-data = <15080 14044 13416 13328 13288 13292>,
			<14927 13995 13419 13321 13290 13291>,
			<14780 13936 13422 13318 13292 13289>,
			<14645 13878 13426 13317 13294 13288>,
			<14528 13831 13429 13317 13295 13287>,
			<14436 13806 13432 13317 13296 13287>,
			<14372 13794 13435 13319 13297 13287>,
			<14305 13784 13437 13322 13298 13288>,
			<14171 13769 13437 13324 13298 13288>,
			<14012 13749 13436 13326 13298 13289>,
			<13979 13712 13440 13327 13299 13290>,
			<13988 13627 13455 13327 13300 13294>,
			<13994 13575 13464 13327 13300 13297>,
			<13955 13576 13456 13333 13301 13298>,
			<13893 13584 13443 13339 13301 13298>,
			<13859 13580 13429 13338 13303 13298>,
			<13834 13571 13413 13332 13307 13298>,
			<13828 13558 13406 13330 13309 13299>,
			<13834 13533 13404 13330 13311 13301>,
			<13842 13509 13402 13331 13312 13303>,
			<13844 13500 13393 13329 13312 13304>,
			<13846 13493 13379 13325 13310 13305>,
			<13850 13477 13371 13319 13306 13303>,
			<13857 13444 13365 13311 13297 13292>,
			<13868 13429 13360 13307 13293 13287>,
			<13889 13437 13357 13307 13293 13287>,
			<13920 13451 13352 13307 13293 13287>,
			<13954 13467 13323 13307 13292 13287>,
			<13995 13488 13272 13307 13292 13288>,
			<14035 13515 13260 13307 13291 13287>,
			<14071 13554 13261 13308 13290 13286>,
			<14110 13596 13263 13309 13289 13285>,
			<14157 13637 13298 13309 13290 13285>,
			<14210 13679 13343 13309 13292 13286>,
			<14260 13725 13350 13309 13292 13287>,
			<14308 13774 13351 13309 13293 13287>,
			<14363 13831 13351 13309 13293 13288>,
			<14431 13901 13354 13307 13292 13287>,
			<14501 13977 13361 13306 13290 13286>,
			<14563 14046 13373 13305 13291 13286>,
			<14623 14116 13389 13304 13291 13287>,
			<14693 14197 13409 13308 13291 13289>,
			<14772 14281 13420 13310 13292 13290>,
			<14751 14256 13423 13306 13290 13288>,
			<14886 14398 13445 13307 13286 13284>,
			<15066 14580 13519 13313 13294 13291>,
			<15174 14673 13556 13318 13298 13296>,
			<15278 14770 13613 13321 13304 13300>,
			<15383 14885 13687 13331 13310 13305>,
			<15515 14981 13765 13340 13309 13303>,
			<15659 15063 13837 13336 13303 13299>,
			<15832 15172 13939 13341 13305 13301>,
			<16052 15352 14214 13355 13312 13307>,
			<16499 15557 14555 13375 13320 13315>,
			<16499 15557 14555 13375 13320 13315>,
			<16499 15557 14555 13375 13320 13315>;
	};

	qcom,pc-temp-y4-lut {
		qcom,lut-col-legend = <(-10) 0 10 25 40 50>;
		qcom,lut-row-legend = <10000 9800 9600 9400 9200 9000>,
			<8800 8600 8400 8200 8000 7800>,
			<7600 7400 7200 7000 6800 6600>,
			<6400 6200 6000 5800 5600 5400>,
			<5200 5000 4800 4600 4400 4200>,
			<4000 3800 3600 3400 3200 3000>,
			<2800 2600 2400 2200 2000 1800>,
			<1600 1400 1200 1000 900 800>,
			<700 600 500 400 300 200>,
			<100 0>;
		qcom,lut-data = <17541 16954 16743 16545 16516 16505>,
			<17648 17156 16765 16544 16509 16501>,
			<17717 17306 16806 16544 16504 16497>,
			<17755 17407 16849 16546 16499 16495>,
			<17772 17462 16882 16548 16497 16494>,
			<17772 17472 16891 16548 16496 16493>,
			<17734 17415 16889 16549 16497 16494>,
			<17698 17345 16886 16551 16500 16496>,
			<17793 17302 16893 16554 16503 16499>,
			<18031 17269 16909 16559 16508 16502>,
			<18211 17347 16922 16566 16513 16505>,
			<18367 17847 16932 16577 16519 16506>,
			<18432 18145 16951 16592 16527 16508>,
			<17972 17853 17092 16626 16540 16514>,
			<17371 17446 17245 16659 16553 16523>,
			<17294 17327 17191 16665 16561 16533>,
			<17285 17272 17016 16667 16567 16543>,
			<17267 17229 16968 16677 16579 16556>,
			<17218 17196 17022 16749 16606 16572>,
			<17155 17159 17061 16803 16636 16591>,
			<17078 17087 16974 16785 16667 16622>,
			<17002 16993 16818 16738 16693 16651>,
			<16986 16917 16738 16674 16667 16633>,
			<16984 16848 16688 16575 16557 16546>,
			<16983 16819 16658 16528 16504 16502>,
			<16982 16817 16638 16521 16497 16495>,
			<16981 16818 16628 16517 16494 16492>,
			<16978 16822 16659 16519 16496 16494>,
			<16971 16828 16724 16524 16504 16501>,
			<16971 16829 16744 16530 16513 16509>,
			<16986 16825 16748 16538 16526 16522>,
			<17003 16822 16747 16545 16541 16537>,
			<17013 16829 16688 16549 16561 16556>,
			<17020 16843 16616 16552 16576 16571>,
			<17028 16858 16619 16554 16573 16569>,
			<17035 16876 16654 16556 16559 16557>,
			<17037 16891 16688 16556 16541 16541>,
			<17034 16905 16723 16543 16514 16514>,
			<17030 16914 16750 16532 16499 16497>,
			<17029 16917 16762 16533 16502 16502>,
			<17032 16917 16772 16534 16508 16510>,
			<17035 16910 16781 16542 16514 16514>,
			<17036 16893 16785 16546 16512 16510>,
			<17020 16846 16753 16533 16498 16496>,
			<17024 16840 16764 16520 16473 16465>,
			<17069 16852 16796 16547 16495 16491>,
			<17102 16882 16827 16567 16516 16523>,
			<17147 16916 16866 16598 16555 16572>,
			<17187 16969 16929 16646 16612 16633>,
			<17220 17037 17024 16692 16627 16623>,
			<17210 17057 17046 16649 16533 16516>,
			<17187 17021 17029 16643 16527 16513>,
			<17204 17022 17066 16703 16557 16534>,
			<17316 17073 17140 16833 16680 16647>,
			<17316 17073 17140 16833 16680 16647>,
			<17316 17073 17140 16833 16680 16647>;
	};

	qcom,pc-temp-y5-lut {
		qcom,lut-col-legend = <(-10) 0 10 25 40 50>;
		qcom,lut-row-legend = <10000 9800 9600 9400 9200 9000>,
			<8800 8600 8400 8200 8000 7800>,
			<7600 7400 7200 7000 6800 6600>,
			<6400 6200 6000 5800 5600 5400>,
			<5200 5000 4800 4600 4400 4200>,
			<4000 3800 3600 3400 3200 3000>,
			<2800 2600 2400 2200 2000 1800>,
			<1600 1400 1200 1000 900 800>,
			<700 600 500 400 300 200>,
			<100 0>;
		qcom,lut-data = <10282 11278 13475 17071 12982 17103>,
			<10435 11070 13592 16957 14197 16461>,
			<10588 10982 13773 16431 14996 15723>,
			<10740 10990 13969 15765 15461 14995>,
			<10891 11076 14129 15228 15671 14383>,
			<11044 11254 14209 15078 15692 13986>,
			<11236 12137 14261 15084 15361 13707>,
			<11361 12911 14292 14992 14901 13479>,
			<11130 12644 14247 14795 14482 13220>,
			<10642 12048 14114 14562 14019 12953>,
			<10846 11914 13839 14218 13684 13016>,
			<12797 11951 13110 13655 13444 13630>,
			<13988 12037 12744 13272 13181 13972>,
			<13250 13845 13465 13149 12729 13691>,
			<12156 16076 14310 13050 12363 13246>,
			<11696 15435 14330 12829 12463 12920>,
			<11408 12907 14219 12515 12784 12628>,
			<11351 12012 14289 12430 12872 12512>,
			<11577 12106 15256 12569 12774 12493>,
			<11772 12257 16058 12841 12704 12536>,
			<11625 12558 16214 14186 13353 13117>,
			<11288 12930 16297 16089 14598 14118>,
			<11023 12762 16290 16269 15492 14701>,
			<10779 11611 16222 15712 16279 15123>,
			<10679 10912 16164 15390 16552 15413>,
			<10680 10814 16331 15463 16548 15638>,
			<10685 10771 16450 15600 16504 15732>,
			<10754 10750 14824 15626 16253 15525>,
			<10922 10723 11596 15633 15679 15097>,
			<10968 10734 10789 15737 15182 14651>,
			<10899 10906 10767 16341 14641 13988>,
			<10848 11083 10790 16950 14411 13656>,
			<10889 11173 12128 17412 14700 13818>,
			<10976 11240 13870 17749 15273 14175>,
			<11049 11284 14056 17774 16110 14876>,
			<11118 11312 13626 17735 17228 16064>,
			<11201 11367 13306 17630 17525 16596>,
			<11337 11574 12546 16935 17186 16630>,
			<11437 11759 11985 16036 16728 16503>,
			<11334 11708 11884 15270 16203 15954>,
			<11100 11631 11791 14653 15821 15540>,
			<10988 11608 11720 14901 15420 15614>,
			<10967 11495 11532 15107 15404 15625>,
			<10805 11282 11542 14601 15523 16210>,
			<10923 11103 11454 14801 14850 15354>,
			<10905 11239 11573 14403 14726 14154>,
			<10964 11183 11445 14339 14332 13987>,
			<11040 11223 11520 13685 14264 13612>,
			<11244 11301 11669 13797 14398 13488>,
			<11395 11520 11809 14134 13914 13240>,
			<11460 11527 11949 14539 14947 14976>,
			<11247 11491 11564 15071 15581 15421>,
			<11073 11473 11512 15476 16761 16350>,
			<11100 11450 11505 16159 17360 17699>,
			<11100 11450 11505 16159 17360 17699>,
			<11100 11450 11505 16159 17360 17699>;
	};

	qcom,pc-temp-y6-lut {
		qcom,lut-col-legend = <(-10) 0 10 25 40 50>;
		qcom,lut-row-legend = <10000 9800 9600 9400 9200 9000>,
			<8800 8600 8400 8200 8000 7800>,
			<7600 7400 7200 7000 6800 6600>,
			<6400 6200 6000 5800 5600 5400>,
			<5200 5000 4800 4600 4400 4200>,
			<4000 3800 3600 3400 3200 3000>,
			<2800 2600 2400 2200 2000 1800>,
			<1600 1400 1200 1000 900 800>,
			<700 600 500 400 300 200>,
			<100 0>;
		qcom,lut-data = <7829 6610 5644 5177 5083 5068>,
			<7717 6582 5650 5175 5082 5066>,
			<7610 6556 5653 5173 5082 5064>,
			<7510 6531 5651 5172 5082 5062>,
			<7419 6509 5648 5171 5082 5062>,
			<7338 6489 5642 5171 5083 5062>,
			<7263 6474 5633 5172 5083 5062>,
			<7199 6457 5623 5173 5084 5063>,
			<7145 6424 5614 5174 5085 5064>,
			<7102 6383 5607 5175 5086 5065>,
			<7100 6382 5606 5177 5088 5067>,
			<7139 6426 5608 5179 5090 5070>,
			<7162 6452 5612 5183 5093 5073>,
			<7011 6398 5636 5195 5096 5075>,
			<6808 6310 5662 5207 5100 5077>,
			<6770 6250 5642 5208 5104 5080>,
			<6759 6200 5582 5205 5108 5083>,
			<6750 6168 5565 5207 5114 5087>,
			<6740 6149 5576 5227 5123 5093>,
			<6730 6133 5584 5242 5131 5100>,
			<6712 6113 5553 5235 5139 5110>,
			<6694 6094 5497 5218 5144 5118>,
			<6692 6073 5469 5196 5134 5111>,
			<6700 6050 5452 5162 5096 5077>,
			<6710 6041 5444 5146 5078 5061>,
			<6727 6056 5442 5145 5076 5059>,
			<6749 6080 5440 5144 5075 5059>,
			<6774 6104 5436 5145 5076 5059>,
			<6802 6132 5431 5148 5078 5061>,
			<6831 6164 5431 5151 5080 5064>,
			<6861 6199 5443 5155 5083 5067>,
			<6894 6237 5457 5159 5087 5070>,
			<6931 6277 5474 5161 5094 5076>,
			<6971 6320 5494 5164 5100 5082>,
			<7012 6366 5516 5166 5099 5082>,
			<7053 6415 5542 5169 5096 5079>,
			<7097 6469 5569 5169 5092 5075>,
			<7146 6530 5600 5166 5084 5067>,
			<7197 6594 5633 5164 5078 5061>,
			<7245 6652 5668 5165 5080 5063>,
			<7295 6711 5708 5168 5083 5066>,
			<7351 6775 5756 5174 5085 5069>,
			<7421 6838 5807 5181 5085 5069>,
			<7417 6816 5803 5176 5081 5064>,
			<7523 6924 5876 5178 5072 5053>,
			<7672 7069 5993 5197 5085 5067>,
			<7762 7146 6056 5210 5095 5080>,
			<7858 7232 6139 5225 5110 5097>,
			<7957 7334 6234 5249 5131 5118>,
			<8067 7429 6336 5272 5134 5113>,
			<8182 7501 6413 5260 5103 5080>,
			<8317 7586 6520 5271 5105 5082>,
			<8513 7731 6765 5316 5121 5094>,
			<8915 7910 7068 5387 5164 5135>,
			<8915 7910 7068 5387 5164 5135>,
			<8915 7910 7068 5387 5164 5135>;
	};
};
